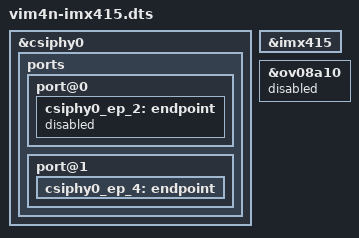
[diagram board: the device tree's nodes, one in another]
/dts-v1/;
/plugin/;

/ {
	fragment@0 {
		target = <&csiphy0>;

		__overlay__ {
			ports {
				port@0 {
					csiphy0_ep_2: endpoint {
						status = "disabled";
					};
				};
				port@1 {
					csiphy0_ep_4: endpoint {
							status = "okay";
					};
				};
			};
		};
	};

	fragment@1 {
		target = <&imx415>;

		__overlay__ {
			status = "okay";
		};
	};

	fragment@2 {
		target = <&ov08a10>;

		__overlay__ {
			status = "disabled";
		};
	};
};
